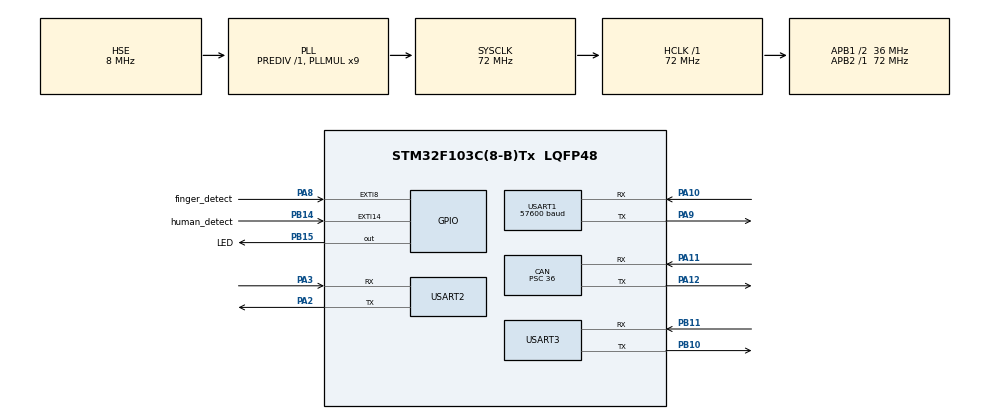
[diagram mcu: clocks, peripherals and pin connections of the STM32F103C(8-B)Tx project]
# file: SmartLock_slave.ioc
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CAN.BS1=CAN_BS1_3TQ
CAN.BS2=CAN_BS2_4TQ
CAN.CalculateBaudRate=125000
CAN.CalculateTimeBit=8000
CAN.CalculateTimeQuantum=1000.0
CAN.NART=ENABLE
CAN.Prescaler=36
CAN.SJW=CAN_SJW_1TQ
Dma.Request0=USART1_RX
Dma.Request1=USART1_TX
Dma.Request2=USART2_RX
Dma.Request3=USART2_TX
Dma.Request4=USART3_RX
Dma.Request5=USART3_TX
Dma.USART1_RX.0.Direction=DMA_PERIPH_TO_MEMORY
Dma.USART1_RX.0.Instance=DMA1_Channel5
Dma.USART1_RX.0.MemDataAlignment=DMA_MDATAALIGN_BYTE
Dma.USART1_RX.0.MemInc=DMA_MINC_ENABLE
Dma.USART1_RX.0.Mode=DMA_NORMAL
Dma.USART1_RX.0.PeriphDataAlignment=DMA_PDATAALIGN_BYTE
Dma.USART1_RX.0.PeriphInc=DMA_PINC_DISABLE
Dma.USART1_RX.0.Priority=DMA_PRIORITY_HIGH
Dma.USART1_TX.1.Direction=DMA_MEMORY_TO_PERIPH
Dma.USART1_TX.1.Instance=DMA1_Channel4
Dma.USART1_TX.1.MemDataAlignment=DMA_MDATAALIGN_BYTE
Dma.USART1_TX.1.MemInc=DMA_MINC_ENABLE
Dma.USART1_TX.1.Mode=DMA_NORMAL
Dma.USART1_TX.1.PeriphDataAlignment=DMA_PDATAALIGN_BYTE
Dma.USART1_TX.1.PeriphInc=DMA_PINC_DISABLE
Dma.USART1_TX.1.Priority=DMA_PRIORITY_MEDIUM
Dma.USART2_RX.2.Direction=DMA_PERIPH_TO_MEMORY
Dma.USART2_RX.2.Instance=DMA1_Channel6
Dma.USART2_RX.2.MemDataAlignment=DMA_MDATAALIGN_BYTE
Dma.USART2_RX.2.MemInc=DMA_MINC_ENABLE
Dma.USART2_RX.2.Mode=DMA_NORMAL
Dma.USART2_RX.2.PeriphDataAlignment=DMA_PDATAALIGN_BYTE
Dma.USART2_RX.2.PeriphInc=DMA_PINC_DISABLE
Dma.USART2_RX.2.Priority=DMA_PRIORITY_VERY_HIGH
Dma.USART2_TX.3.Direction=DMA_MEMORY_TO_PERIPH
Dma.USART2_TX.3.Instance=DMA1_Channel7
Dma.USART2_TX.3.MemDataAlignment=DMA_MDATAALIGN_BYTE
Dma.USART2_TX.3.MemInc=DMA_MINC_ENABLE
Dma.USART2_TX.3.Mode=DMA_NORMAL
Dma.USART2_TX.3.PeriphDataAlignment=DMA_PDATAALIGN_BYTE
Dma.USART2_TX.3.PeriphInc=DMA_PINC_DISABLE
Dma.USART2_TX.3.Priority=DMA_PRIORITY_MEDIUM
Dma.USART3_RX.4.Direction=DMA_PERIPH_TO_MEMORY
Dma.USART3_RX.4.Instance=DMA1_Channel3
Dma.USART3_RX.4.MemDataAlignment=DMA_MDATAALIGN_BYTE
Dma.USART3_RX.4.MemInc=DMA_MINC_ENABLE
Dma.USART3_RX.4.Mode=DMA_NORMAL
Dma.USART3_RX.4.PeriphDataAlignment=DMA_PDATAALIGN_BYTE
Dma.USART3_RX.4.PeriphInc=DMA_PINC_DISABLE
Dma.USART3_RX.4.Priority=DMA_PRIORITY_MEDIUM
Dma.USART3_TX.5.Direction=DMA_MEMORY_TO_PERIPH
Dma.USART3_TX.5.Instance=DMA1_Channel2
Dma.USART3_TX.5.MemDataAlignment=DMA_MDATAALIGN_BYTE
Dma.USART3_TX.5.MemInc=DMA_MINC_ENABLE
Dma.USART3_TX.5.Mode=DMA_NORMAL
Dma.USART3_TX.5.PeriphDataAlignment=DMA_PDATAALIGN_BYTE
Dma.USART3_TX.5.PeriphInc=DMA_PINC_DISABLE
Dma.USART3_TX.5.Priority=DMA_PRIORITY_MEDIUM
Mcu.Family=STM32F1
Mcu.Name=STM32F103C(8-B)Tx
Mcu.Package=LQFP48
NVIC.CAN1_RX1_IRQn=true\:1\:0\:true\:false\:true\:true\:true\:true
NVIC.CAN1_SCE_IRQn=true\:1\:0\:true\:false\:true\:true\:true\:true
NVIC.DMA1_Channel2_IRQn=true\:1\:0\:true\:false\:true\:false\:true\:true
NVIC.DMA1_Channel3_IRQn=true\:1\:0\:true\:false\:true\:false\:true\:true
NVIC.DMA1_Channel4_IRQn=true\:1\:0\:true\:false\:true\:false\:true\:true
NVIC.DMA1_Channel5_IRQn=true\:1\:0\:true\:false\:true\:false\:true\:true
NVIC.DMA1_Channel6_IRQn=true\:1\:0\:true\:false\:true\:false\:true\:true
NVIC.DMA1_Channel7_IRQn=true\:1\:0\:true\:false\:true\:false\:true\:true
NVIC.EXTI15_10_IRQn=true\:1\:0\:true\:false\:true\:true\:true\:true
NVIC.EXTI9_5_IRQn=true\:1\:0\:true\:false\:true\:true\:true\:true
NVIC.PriorityGroup=NVIC_PRIORITYGROUP_4
NVIC.TIM4_IRQn=true\:2\:0\:true\:false\:true\:true\:true\:true
NVIC.USART1_IRQn=true\:0\:0\:true\:false\:true\:false\:true\:true
NVIC.USART2_IRQn=true\:0\:0\:true\:false\:true\:false\:true\:true
NVIC.USART3_IRQn=true\:1\:0\:true\:false\:true\:true\:true\:true
NVIC.USB_HP_CAN1_TX_IRQn=true\:1\:0\:true\:false\:true\:true\:true\:true
NVIC.USB_LP_CAN1_RX0_IRQn=true\:1\:0\:true\:false\:true\:true\:true\:true
PA10.GPIO_PuPd=GPIO_NOPULL
PA10.Mode=Asynchronous
PA10.Signal=USART1_RX
PA11.Mode=CAN_Activate
PA11.Signal=CAN_RX
PA12.Mode=CAN_Activate
PA12.Signal=CAN_TX
PA13.Mode=Serial_Wire
PA13.Signal=SYS_JTMS-SWDIO
PA14.Mode=Serial_Wire
PA14.Signal=SYS_JTCK-SWCLK
PA2.Mode=Asynchronous
PA2.Signal=USART2_TX
PA3.Mode=Asynchronous
PA3.Signal=USART2_RX
PA8.GPIO_Label=finger_detect
PA8.GPIO_PuPd=GPIO_PULLDOWN
PA8.Signal=GPXTI8
PA9.Mode=Asynchronous
PA9.Signal=USART1_TX
PB10.Mode=Asynchronous
PB10.Signal=USART3_TX
PB11.Mode=Asynchronous
PB11.Signal=USART3_RX
PB14.GPIO_Label=human_detect
PB14.GPIO_ModeDefaultEXTI=GPIO_MODE_IT_RISING_FALLING
PB14.GPIO_PuPd=GPIO_PULLDOWN
PB14.Signal=GPXTI14
PB15.GPIO_Label=LED
PB15.GPIO_ModeDefaultOutputPP=GPIO_MODE_OUTPUT_OD
PB15.GPIO_PuPd=GPIO_NOPULL
PB15.GPIO_Speed=GPIO_SPEED_FREQ_LOW
PB15.PinState=GPIO_PIN_RESET
PB15.Signal=GPIO_Output
PD0-OSC_IN.Mode=HSE-External-Oscillator
PD0-OSC_IN.Signal=RCC_OSC_IN
PD1-OSC_OUT.Mode=HSE-External-Oscillator
PD1-OSC_OUT.Signal=RCC_OSC_OUT
ProjectManager.HeapSize=0x1200
ProjectManager.StackSize=0x1200
ProjectManager.TargetToolchain=Makefile
RCC.AHBFreq_Value=72000000
RCC.APB1CLKDivider=RCC_HCLK_DIV2
RCC.APB1Freq_Value=36000000
RCC.APB1TimFreq_Value=72000000
RCC.APB2Freq_Value=72000000
RCC.APB2TimFreq_Value=72000000
RCC.HCLKFreq_Value=72000000
RCC.PLLMUL=RCC_PLL_MUL9
RCC.PLLSourceVirtual=RCC_PLLSOURCE_HSE
RCC.SYSCLKFreq_VALUE=72000000
RCC.SYSCLKSource=RCC_SYSCLKSOURCE_PLLCLK
RCC.USBFreq_Value=72000000
TIM4.Period=10000-1
TIM4.Prescaler=72-1
USART1.BaudRate=57600
USART1.VirtualMode=VM_ASYNC
USART2.VirtualMode=VM_ASYNC
USART3.VirtualMode=VM_ASYNC
VP_TIM3_VS_ClockSourceINT.Mode=Internal
VP_TIM4_VS_ClockSourceINT.Mode=Internal
board=custom

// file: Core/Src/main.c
/* USER CODE BEGIN Header */
/**
 ******************************************************************************
 * @file           : main.c
 * @brief          : Main program body
 ******************************************************************************
 * @attention
 *
 * Copyright (c) 2024 STMicroelectronics.
 * All rights reserved.
 *
 * This software is licensed under terms that can be found in the LICENSE file
 * in the root directory of this software component.
 * If no LICENSE file comes with this software, it is provided AS-IS.
 *
 ******************************************************************************
 */
/* USER CODE END Header */
#include "main.h"
#include "can.h"
#include "dma.h"
#include "tim.h"
#include "usart.h"
#include "gpio.h"

/* USER CODE BEGIN Includes */
#include "bsp/dwt/dwt.h"
/* USER CODE END Includes */

void SystemClock_Config(void);

int main(void)
{

    __disable_irq();

  /* MCU Configuration--------------------------------------------------------*/

  /* Reset of all peripherals, Initializes the Flash interface and the Systick. */
  HAL_Init();

  /* Configure the system clock */
  SystemClock_Config();

  /* USER CODE BEGIN SysInit */
    DWT_Init();
  /* USER CODE END SysInit */

  /* Initialize all configured peripherals */
  MX_GPIO_Init();
  MX_DMA_Init();
  MX_USART1_UART_Init();
  MX_TIM4_Init();
  MX_USART2_UART_Init();
  MX_CAN_Init();
  MX_TIM3_Init();
  MX_USART3_UART_Init();
  /* USER CODE BEGIN 2 */

    app_main();

  /* USER CODE END 2 */

  /* Infinite loop */
  /* USER CODE BEGIN WHILE */

    // never reach here
    while (1) {
    /* USER CODE END WHILE */

    }
}

void SystemClock_Config(void)
{
  RCC_OscInitTypeDef RCC_OscInitStruct = {0};
  RCC_ClkInitTypeDef RCC_ClkInitStruct = {0};

  /** Initializes the RCC Oscillators according to the specified parameters
  * in the RCC_OscInitTypeDef structure.
  */
  RCC_OscInitStruct.OscillatorType = RCC_OSCILLATORTYPE_HSE;
  RCC_OscInitStruct.HSEState = RCC_HSE_ON;
  RCC_OscInitStruct.HSEPredivValue = RCC_HSE_PREDIV_DIV1;
  RCC_OscInitStruct.HSIState = RCC_HSI_ON;
  RCC_OscInitStruct.PLL.PLLState = RCC_PLL_ON;
  RCC_OscInitStruct.PLL.PLLSource = RCC_PLLSOURCE_HSE;
  RCC_OscInitStruct.PLL.PLLMUL = RCC_PLL_MUL9;
  if (HAL_RCC_OscConfig(&RCC_OscInitStruct) != HAL_OK)
  {
    Error_Handler();
  }

  /** Initializes the CPU, AHB and APB buses clocks
  */
  RCC_ClkInitStruct.ClockType = RCC_CLOCKTYPE_HCLK|RCC_CLOCKTYPE_SYSCLK
                              |RCC_CLOCKTYPE_PCLK1|RCC_CLOCKTYPE_PCLK2;
  RCC_ClkInitStruct.SYSCLKSource = RCC_SYSCLKSOURCE_PLLCLK;
  RCC_ClkInitStruct.AHBCLKDivider = RCC_SYSCLK_DIV1;
  RCC_ClkInitStruct.APB1CLKDivider = RCC_HCLK_DIV2;
  RCC_ClkInitStruct.APB2CLKDivider = RCC_HCLK_DIV1;

  if (HAL_RCC_ClockConfig(&RCC_ClkInitStruct, FLASH_LATENCY_2) != HAL_OK)
  {
    Error_Handler();
  }
}

/* USER CODE BEGIN 4 */
__weak void app_main() {
    while (1) {}
}
/* USER CODE END 4 */

void Error_Handler(void)
{
    __disable_irq();
    while (1) {}
}
